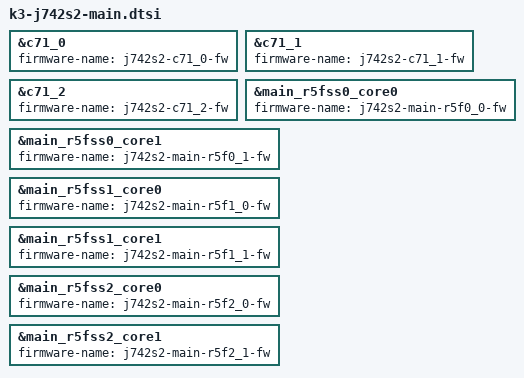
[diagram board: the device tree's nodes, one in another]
// SPDX-License-Identifier: GPL-2.0
/*
 * Copyright (C) 2024 Texas Instruments Incorporated - https://www.ti.com/
 *
 * EVM Board Schematics: https://www.ti.com/lit/zip/SPAC001
 */

/delete-node/ &c71_3;

/delete-node/ &vpu1;

&c71_0 {
	firmware-name = "j742s2-c71_0-fw";
};

&c71_1 {
	firmware-name = "j742s2-c71_1-fw";
};

&c71_2 {
	firmware-name = "j742s2-c71_2-fw";
};

&main_r5fss0_core0 {
	firmware-name = "j742s2-main-r5f0_0-fw";
};

&main_r5fss0_core1 {
	firmware-name = "j742s2-main-r5f0_1-fw";
};

&main_r5fss1_core0 {
	firmware-name = "j742s2-main-r5f1_0-fw";
};

&main_r5fss1_core1 {
	firmware-name = "j742s2-main-r5f1_1-fw";
};

&main_r5fss2_core0 {
	firmware-name = "j742s2-main-r5f2_0-fw";
};

&main_r5fss2_core1 {
	firmware-name = "j742s2-main-r5f2_1-fw";
};

